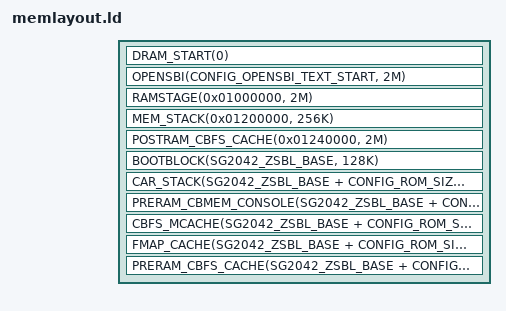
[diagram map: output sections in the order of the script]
/* SPDX-License-Identifier: GPL-2.0-only */
#include <memlayout.h>
#include <arch/header.ld>
#include <soc/addressmap.h>

SECTIONS
{
	DRAM_START(0)
	OPENSBI(CONFIG_OPENSBI_TEXT_START, 2M)
	RAMSTAGE(0x01000000, 2M)
	MEM_STACK(0x01200000, 256K)
	POSTRAM_CBFS_CACHE(0x01240000, 2M)

	/* The SCP releases all 64 harts at the first byte of zsbl.bin. */
	BOOTBLOCK(SG2042_ZSBL_BASE, 128K)
	CAR_STACK(SG2042_ZSBL_BASE + CONFIG_ROM_SIZE, 256K)
	PRERAM_CBMEM_CONSOLE(SG2042_ZSBL_BASE + CONFIG_ROM_SIZE + 256K, 8K)
	CBFS_MCACHE(SG2042_ZSBL_BASE + CONFIG_ROM_SIZE + 264K, 8K)
	FMAP_CACHE(SG2042_ZSBL_BASE + CONFIG_ROM_SIZE + 272K, 4K)
	PRERAM_CBFS_CACHE(SG2042_ZSBL_BASE + CONFIG_ROM_SIZE + 276K, 128K)
}
